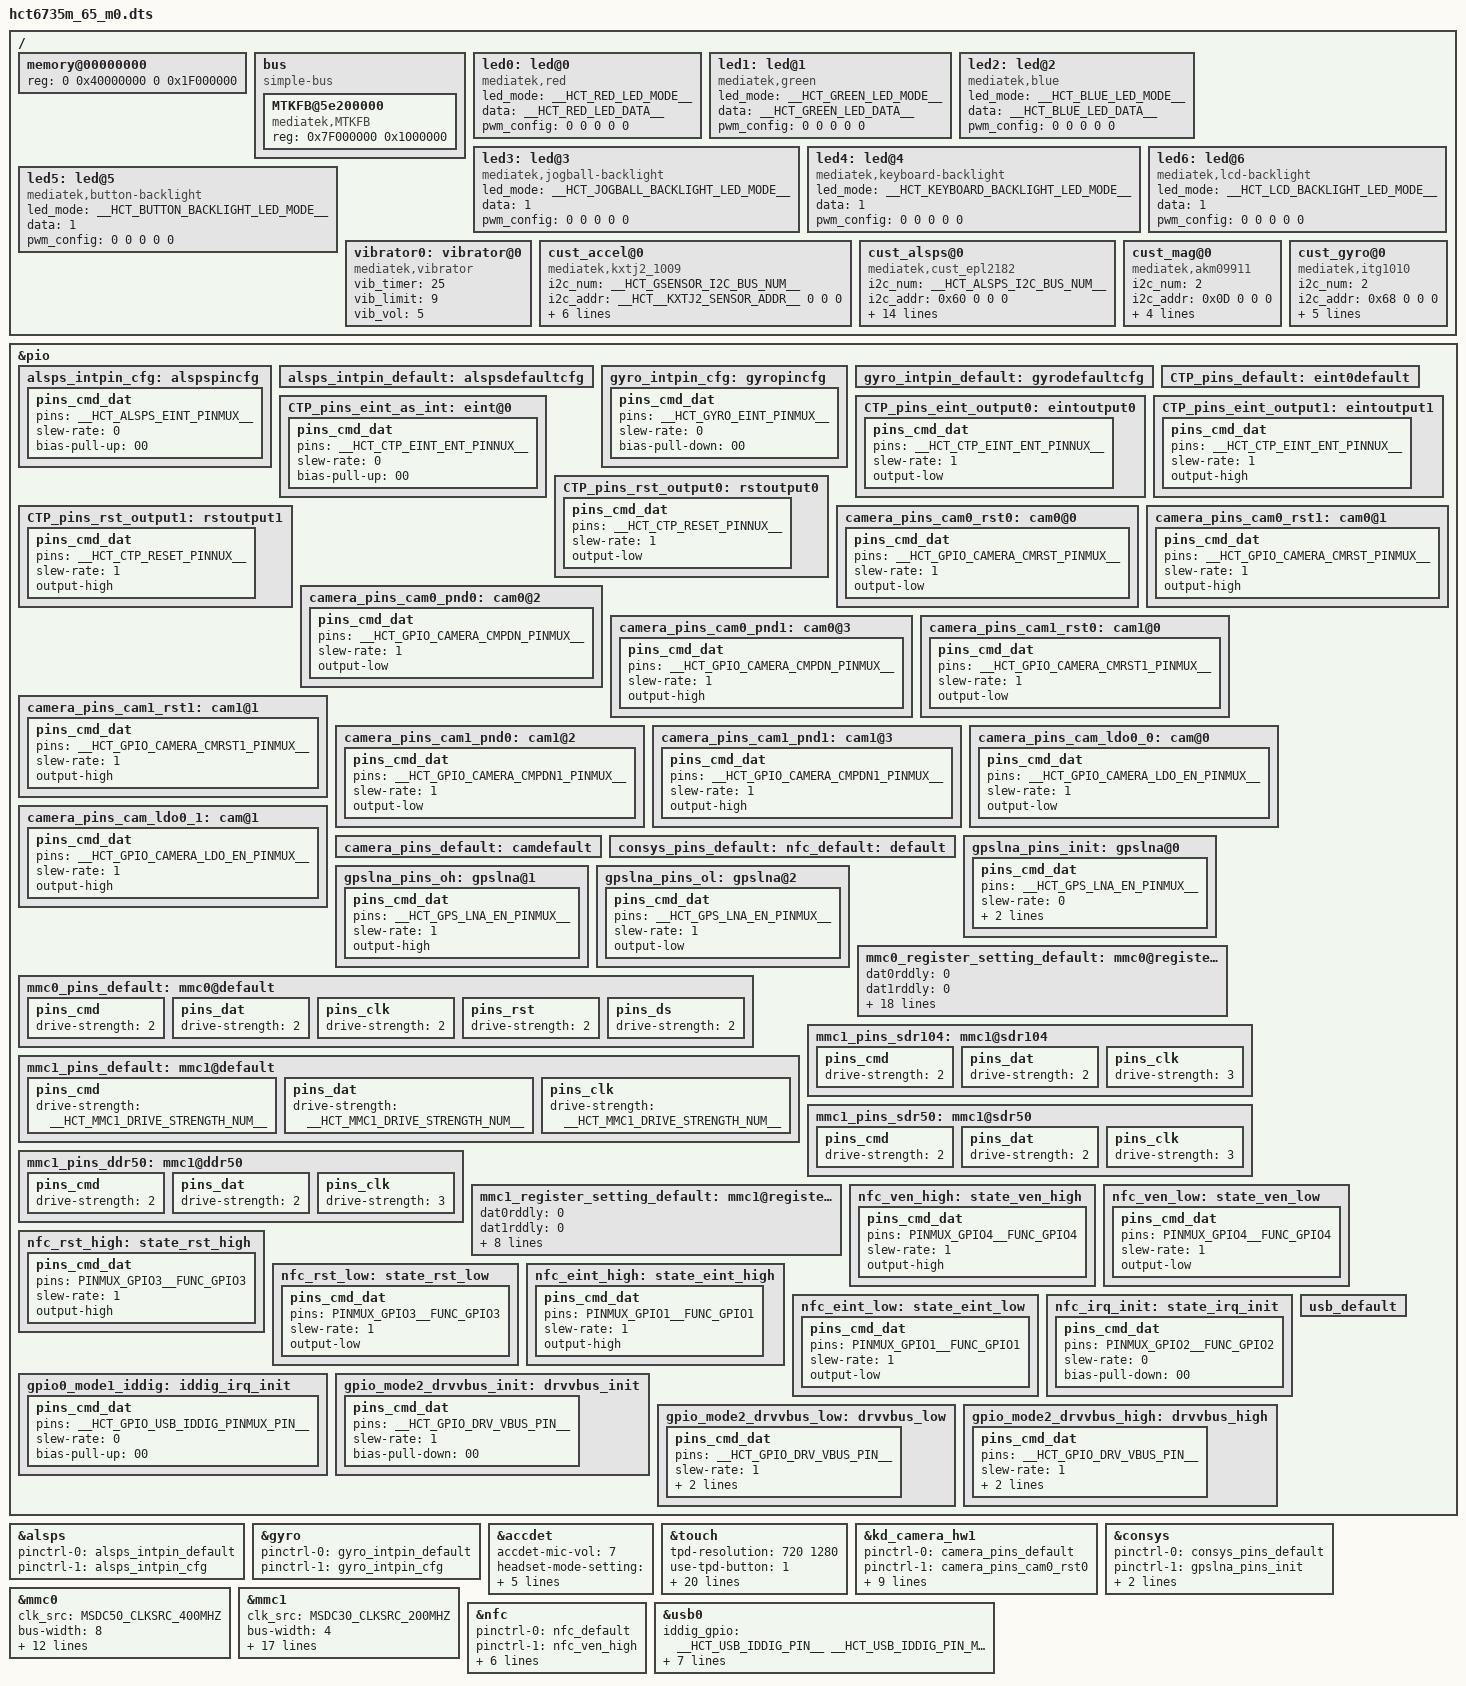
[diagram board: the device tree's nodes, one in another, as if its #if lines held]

/dts-v1/;

#include "hct_board_config.h"
#include "mt6735m.dtsi"
#include "hct_board_dts_config.h"

/ {
memory@00000000 {
		device_type = "memory";
		reg = <0 0x40000000 0 0x1F000000>;
	};

	bus {
		compatible = "simple-bus";
		#address-cells = <1>;
		#size-cells = <1>;
		ranges = <0 0 0 0xffffffff>;

		MTKFB@5e200000 {
			compatible = "mediatek,MTKFB";
			reg = <0x7F000000 0x1000000>;
		};

	};
	led0:led@0 {
		compatible = "mediatek,red";
		led_mode = <__HCT_RED_LED_MODE__>;
#if __HCT_RED_LED_MODE__ ==	__HCT_MT65XX_LED_MODE_PMIC__
		data = <__HCT_RED_LED_DATA__>;
#else
		data = <1>;
#endif
		pwm_config = <0 0 0 0 0>;
	};
	led1:led@1 {
		compatible = "mediatek,green";
		led_mode = <__HCT_GREEN_LED_MODE__>;
#if __HCT_GREEN_LED_MODE__ ==	__HCT_MT65XX_LED_MODE_PMIC__
		data = <__HCT_GREEN_LED_DATA__>;
#else
		data = <1>;
#endif
		pwm_config = <0 0 0 0 0>;
	};
	led2:led@2 {
		compatible = "mediatek,blue";
		led_mode = <__HCT_BLUE_LED_MODE__>;
#if __HCT_BLUE_LED_MODE__ ==	__HCT_MT65XX_LED_MODE_PMIC__
		data = <__HCT_BLUE_LED_DATA__>;
#else
		data = <1>;
#endif
		pwm_config = <0 0 0 0 0>;
	};
	led3:led@3 {
		compatible = "mediatek,jogball-backlight";
		led_mode = <__HCT_JOGBALL_BACKLIGHT_LED_MODE__>;
		data = <1>;
		pwm_config = <0 0 0 0 0>;
	};
	led4:led@4 {
		compatible = "mediatek,keyboard-backlight";
		led_mode = <__HCT_KEYBOARD_BACKLIGHT_LED_MODE__>;
		data = <1>;
		pwm_config = <0 0 0 0 0>;
	};
	led5:led@5 {
		compatible = "mediatek,button-backlight";
		led_mode = <__HCT_BUTTON_BACKLIGHT_LED_MODE__>;
		data = <1>;
		pwm_config = <0 0 0 0 0>;
	};
	led6:led@6 {
		compatible = "mediatek,lcd-backlight";
		led_mode = <__HCT_LCD_BACKLIGHT_LED_MODE__>;
		data = <1>;
		pwm_config = <0 0 0 0 0>;
	};
	vibrator0:vibrator@0 {
		compatible = "mediatek,vibrator";
		vib_timer = <25>;
		vib_limit = <9>;
		vib_vol= <5>;
	};
 /* sensor standardization */
		cust_accel@0 {
		compatible				= "mediatek,kxtj2_1009";
		i2c_num				        = <__HCT_GSENSOR_I2C_BUS_NUM__>;
		i2c_addr				= <__HCT__KXTJ2_SENSOR_ADDR__ 0 0 0>;
		direction				= <__HCT__KXTJ2_SENSOR_DIRECTION__>;
		power_id				= <0xffff>;
		power_vol				= <0>;
		firlen					= <0>;
		is_batch_supported			= <__HCT__KXTJ2_SENSOR_BATCH_SUPPORT__>;
		};

		cust_alsps@0 {
		compatible				= "mediatek,cust_epl2182";
		i2c_num				= <__HCT_ALSPS_I2C_BUS_NUM__>;
		i2c_addr				= <0x60 0 0 0>;
		polling_mode_ps			= <0>;
		polling_mode_als		= <1>;
		power_id				= <0xffff>;
		power_vol				= <0>;
		als_level = <0 328 861 1377 3125 7721 7767 12621 23062 28430 33274 47116 57694 57694 65535>;
		als_value = <0 133 304 502 1004 2005 3058 5005 8008 10010 12000 16000 20000 20000 20000 20000>;
		ps_threshold_high		=  <__HCT_EPL2182_PS_THRELD_HIGH__>;
		ps_threshold_low		=  <__HCT_EPL2182_PS_THRELD_LOW__>;
		is_batch_supported_ps	= <0>;
		is_batch_supported_als	= <0>;
		};

		cust_mag@0 {
		compatible				= "mediatek,akm09911";
		i2c_num					= <2>;
		i2c_addr				= <0x0D 0 0 0>;
		direction				= <1>;
		power_id				= <0xffff>;
		power_vol				= <0>;
		is_batch_supported			= <0>;
		};

		cust_gyro@0 {
		compatible				= "mediatek,itg1010";
		i2c_num					= <2>;
		i2c_addr				= <0x68 0 0 0>;
		direction				= <3>;
		power_id				= <0xffff>;
		power_vol				= <0>;
		firlen					= <0>;
		is_batch_supported			= <0>;
		};
};
/* sensor gpio standization */
&pio {
	alsps_intpin_cfg: alspspincfg {
#if __HCT_ALSPS_EINT_PINMUX__
	    pins_cmd_dat {
			pins = <__HCT_ALSPS_EINT_PINMUX__>;
			slew-rate = <0>;
			bias-pull-up = <00>;
		};
#endif
	};

	alsps_intpin_default: alspsdefaultcfg {

	};

	gyro_intpin_cfg: gyropincfg {
#if __HCT_GYRO_EINT_PINMUX__
	    pins_cmd_dat {
			pins = <__HCT_GYRO_EINT_PINMUX__>;
			slew-rate = <0>;
			bias-pull-down = <00>;
		};
#endif
	};

	gyro_intpin_default: gyrodefaultcfg {

	};
};
&alsps {
	pinctrl-names = "pin_default", "pin_cfg";
	pinctrl-0 = <&alsps_intpin_default>;
	pinctrl-1 = <&alsps_intpin_cfg>;
	status = "okay";

};

&gyro {
	pinctrl-names = "pin_default", "pin_cfg";
	pinctrl-0 = <&gyro_intpin_default>;
	pinctrl-1 = <&gyro_intpin_cfg>;
	status = "okay";

};
/* sensor end */
&accdet {
		accdet-mic-vol = <7>;
		headset-mode-setting = <0x500 0x200 1 0x1F0 0x800 0x800 0x20>;
		accdet-plugout-debounce = <20>;
		/*1:ACC mode, 2:low cost without in bias, 6:low cost with in bias*/
		accdet-mic-mode = <__HCT_ACCDET_MIC_MODE__>;
		/*0--MD_MAX--UP_MAX--DW_MAX*/
		headset-three-key-threshold = <0 80 220 500>;
		/*0--MD_MAX--VOICE_MAX--UP_MAX--DW_MAX*/
		headset-four-key-threshold = <0 58 121 192 450>;
};
&touch {
	tpd-resolution = <720 1280>;
	use-tpd-button = <1>;
	tpd-key-num = <3>;
	tpd-key-local= <139 172 158 0>;
	tpd-key-dim-local = <66 2000 100 40 300 2000 100 40 418 2000 100 40 0 0 0 0>;
	tpd-max-touch-num = <5>;
	tpd-filter-enable = <1>;
	tpd-filter-pixel-density = <93>;
	tpd-filter-custom-prameters = <0 0 0 0 0 0 0 0 0 0 0 0>;
	tpd-filter-custom-speed = <0 0 0>;
	pinctrl-names = "default", "state_eint_as_int", "state_eint_output0", "state_eint_output1",
		"state_rst_output0", "state_rst_output1","state_eint_as_int_bias_dis","aw9136_int_as_eint","aw9136_pdn_out0","aw9136_pdn_out1";
	pinctrl-0 = <&CTP_pins_default>;
	pinctrl-1 = <&CTP_pins_eint_as_int>;
	pinctrl-2 = <&CTP_pins_eint_output0>;
	pinctrl-3 = <&CTP_pins_eint_output1>;
	pinctrl-4 = <&CTP_pins_rst_output0>;
	pinctrl-5 = <&CTP_pins_rst_output1>;
	pinctrl-6 = <&ctp_pins_eint_as_int_bias_disable>;
	pinctrl-7 = <&CTP_pins_aw9136_int_as_eint>;
	pinctrl-8 = <&CTP_pins_aw9136_pdn_out0>;
	pinctrl-9 = <&CTP_pins_aw9136_pdn_out1>;
	status = "okay";
};
&pio {
	CTP_pins_default: eint0default {
	};
	CTP_pins_eint_as_int: eint@0 {
		pins_cmd_dat {
			pins = <__HCT_CTP_EINT_ENT_PINNUX__>;
			slew-rate = <0>;
			bias-pull-up = <00>;
		};
	};
	CTP_pins_eint_output0: eintoutput0 {
		pins_cmd_dat {
			pins = <__HCT_CTP_EINT_ENT_PINNUX__>;
			slew-rate = <1>;
			output-low;
		};
	};
	CTP_pins_eint_output1: eintoutput1 {
		pins_cmd_dat {
			pins = <__HCT_CTP_EINT_ENT_PINNUX__>;
			slew-rate = <1>;
			output-high;
		};
	};
	CTP_pins_rst_output0: rstoutput0 {
		pins_cmd_dat {
			pins = <__HCT_CTP_RESET_PINNUX__>;
			slew-rate = <1>;
			output-low;
		};
	};
	CTP_pins_rst_output1: rstoutput1 {
		pins_cmd_dat {
			pins = <__HCT_CTP_RESET_PINNUX__>;
			slew-rate = <1>;
			output-high;
		};
	};
};
/* TOUCH end */
/* CAMERA GPIO standardization */
&pio {
	camera_pins_cam0_rst0: cam0@0 {
	    pins_cmd_dat {
			pins = <__HCT_GPIO_CAMERA_CMRST_PINMUX__>;/*GPIO_CAMERA_CMRST_PIN*/
			slew-rate = <1>; /*direction 0:in, 1:out*/
			output-low;/*direction out used only. output_low or high*/
		};
	};
	camera_pins_cam0_rst1: cam0@1 {
	    pins_cmd_dat {
			pins = <__HCT_GPIO_CAMERA_CMRST_PINMUX__>;/*GPIO_CAMERA_CMRST_PIN*/
			slew-rate = <1>;
			output-high;
		};
	};
	camera_pins_cam0_pnd0: cam0@2 {
	    pins_cmd_dat {
			pins = <__HCT_GPIO_CAMERA_CMPDN_PINMUX__>;/*GPIO_CAMERA_CMPDN_PIN*/
			slew-rate = <1>;
			output-low;
		};
	};
	camera_pins_cam0_pnd1: cam0@3 {
	    pins_cmd_dat {
			pins = <__HCT_GPIO_CAMERA_CMPDN_PINMUX__>;/*GPIO_CAMERA_CMPDN_PIN*/
			slew-rate = <1>;
			output-high;
		};
	};
	camera_pins_cam1_rst0: cam1@0 {
	    pins_cmd_dat {
			pins = <__HCT_GPIO_CAMERA_CMRST1_PINMUX__>;/*GPIO_CAMERA_CMRST1_PIN*/
			slew-rate = <1>; /*direction 0:in, 1:out*/
			output-low;/*direction out used only. output_low or high*/
		};
	};
	camera_pins_cam1_rst1: cam1@1 {
	    pins_cmd_dat {
			pins = <__HCT_GPIO_CAMERA_CMRST1_PINMUX__>;/*GPIO_CAMERA_CMRST1_PIN*/
			slew-rate = <1>;
			output-high;
		};
	};
	camera_pins_cam1_pnd0: cam1@2 {
	    pins_cmd_dat {
			pins = <__HCT_GPIO_CAMERA_CMPDN1_PINMUX__>;/*GPIO_CAMERA_CMPDN1_PIN*/
			slew-rate = <1>;
			output-low;
		};
	};
	camera_pins_cam1_pnd1: cam1@3 {
	    pins_cmd_dat {
			pins = <__HCT_GPIO_CAMERA_CMPDN1_PINMUX__>;/*GPIO_CAMERA_CMPDN1_PIN*/
			slew-rate = <1>;
			output-high;
		};
	};
	camera_pins_cam_ldo0_0: cam@0 {
#if __HCT_GPIO_CAMERA_LDO_EN_PINMUX__
	    pins_cmd_dat {
			pins = <__HCT_GPIO_CAMERA_LDO_EN_PINMUX__>;/*GPIO_SPI_MOSI_PIN*/
			slew-rate = <1>;
			output-low;
		};
#endif
	};
	camera_pins_cam_ldo0_1: cam@1 {
#if __HCT_GPIO_CAMERA_LDO_EN_PINMUX__
		pins_cmd_dat {
			pins = <__HCT_GPIO_CAMERA_LDO_EN_PINMUX__>;/*GPIO_SPI_MOSI_PIN*/
			slew-rate = <1>;
			output-high;
		};
#endif
	};
	camera_pins_default: camdefault {
	};

};

&kd_camera_hw1 {
	pinctrl-names = "default", "cam0_rst0", "cam0_rst1", "cam0_pnd0", "cam0_pnd1",
			"cam1_rst0", "cam1_rst1", "cam1_pnd0", "cam1_pnd1","cam_ldo0_0", "cam_ldo0_1";
	pinctrl-0 = <&camera_pins_default>;
	pinctrl-1 = <&camera_pins_cam0_rst0>;
	pinctrl-2 = <&camera_pins_cam0_rst1>;
	pinctrl-3 = <&camera_pins_cam0_pnd0>;
	pinctrl-4 = <&camera_pins_cam0_pnd1>;
	pinctrl-5 = <&camera_pins_cam1_rst0>;
	pinctrl-6 = <&camera_pins_cam1_rst1>;
	pinctrl-7 = <&camera_pins_cam1_pnd0>;
	pinctrl-8 = <&camera_pins_cam1_pnd1>;
	pinctrl-9 = <&camera_pins_cam_ldo0_0>;
	pinctrl-10 = <&camera_pins_cam_ldo0_1>;
	status = "okay";

};
/* CAMERA GPIO end */

/* CONSYS GPIO standardization */
&pio {
	consys_pins_default: default {

	};

	gpslna_pins_init: gpslna@0 {
#if __HCT_GPS_LNA_EN_PINMUX__
	    pins_cmd_dat {
			pins = <__HCT_GPS_LNA_EN_PINMUX__>;
			slew-rate = <0>;
			bias-disable;
			output-low;

		};
#endif
	};

	gpslna_pins_oh: gpslna@1 {
#if __HCT_GPS_LNA_EN_PINMUX__
	    pins_cmd_dat {
			pins = <__HCT_GPS_LNA_EN_PINMUX__>;
			slew-rate = <1>;
			output-high;
		};
#endif
	};

	gpslna_pins_ol: gpslna@2 {
#if __HCT_GPS_LNA_EN_PINMUX__
	    pins_cmd_dat {
			pins = <__HCT_GPS_LNA_EN_PINMUX__>;
			slew-rate = <1>;
			output-low;
		};
#endif
	};

};

&consys {
	pinctrl-names = "default", "gps_lna_state_init", "gps_lna_state_oh", "gps_lna_state_ol";
	pinctrl-0 = <&consys_pins_default>;
	pinctrl-1 = <&gpslna_pins_init>;
	pinctrl-2 = <&gpslna_pins_oh>;
	pinctrl-3 = <&gpslna_pins_ol>;
	status = "okay";

};
/* CONSYS end */

/* mmc start */
&mmc0 {
		clk_src = /bits/ 8 <MSDC50_CLKSRC_400MHZ>;
		bus-width = <8>;
		max-frequency = <200000000>;
		cap-mmc-highspeed;
		msdc-sys-suspend;
		mmc-ddr-1_8v;
		mmc-hs200-1_8v;
		mmc-hs400-1_8v;
		non-removable;
		pinctl = <&mmc0_pins_default>;
		register_setting = <&mmc0_register_setting_default>;
		host_function = /bits/ 8 <MSDC_EMMC>;
		bootable;
		status = "okay";
};

&mmc1 {
		clk_src = /bits/ 8 <MSDC30_CLKSRC_200MHZ>;
		bus-width = <4>;
		max-frequency = <200000000>;
		msdc-sys-suspend;
		cap-sd-highspeed;
		sd-uhs-sdr12;
		sd-uhs-sdr25;
		sd-uhs-sdr50;
		sd-uhs-sdr104;
		sd-uhs-ddr50;
		pinctl = <&mmc1_pins_default>;
		pinctl_sdr104 = <&mmc1_pins_sdr104>;
		pinctl_sdr50 = <&mmc1_pins_sdr50>;
		pinctl_ddr50 = <&mmc1_pins_ddr50>;
		register_setting = <&mmc1_register_setting_default>;
		host_function = /bits/ 8 <MSDC_SD>;
		cd_level = /bits/ 8 <MSDC_CD_LOW>;
#if __HCT_SD_CARD_HOTPLUG_SUPPORT__
		cd-gpios = <&pio __HCT_MSDC_CD_GPIO_PIN_NUM__ 0>;
#else
		non-removable;
#endif
		status = "okay";
};

&pio {
	mmc0_pins_default: mmc0@default {
			pins_cmd {
				drive-strength = /bits/ 8 <2>;
			};
			pins_dat {
				drive-strength = /bits/ 8 <2>;
			};
			pins_clk {
				drive-strength = /bits/ 8 <2>;
			};
			pins_rst {
				drive-strength = /bits/ 8 <2>;
			};
			pins_ds {
				drive-strength = /bits/ 8 <2>;
			};
	};

	mmc0_register_setting_default: mmc0@register_default {
		dat0rddly      = /bits/ 8 <0>;
		dat1rddly      = /bits/ 8 <0>;
		dat2rddly      = /bits/ 8 <0>;
		dat3rddly      = /bits/ 8 <0>;
		dat4rddly      = /bits/ 8 <0>;
		dat5rddly      = /bits/ 8 <0>;
		dat6rddly      = /bits/ 8 <0>;
		dat7rddly      = /bits/ 8 <0>;
		datwrddly      = /bits/ 8 <0>;
		cmdrrddly      = /bits/ 8 <0>;
		cmdrddly       = /bits/ 8 <0>;
		cmd_edge = /bits/ 8 <MSDC_SMPL_FALLING>;
		rdata_edge = /bits/ 8 <MSDC_SMPL_FALLING>;
		wdata_edge = /bits/ 8 <MSDC_SMPL_FALLING>;

		ett-hs200-cells = <12>;
		ett-hs200-default = <OFFSET_MSDC_PATCH_BIT0	MSDC_PB0_INT_DAT_LATCH_CK_SEL 0x0
			OFFSET_MSDC_PATCH_BIT0	MSDC_PB0_CKGEN_MSDC_DLY_SEL   0x0
			OFFSET_MSDC_PATCH_BIT1	MSDC_PB1_CMD_RSP_TA_CNTR      0x1
			OFFSET_MSDC_IOCON		MSDC_IOCON_RSPL               0x1
			OFFSET_MSDC_PAD_TUNE0	MSDC_PAD_TUNE0_CMDRDLY        0x0
			OFFSET_MSDC_PAD_TUNE0	MSDC_PAD_TUNE0_CMDRRDLY       0x6
			OFFSET_MSDC_PATCH_BIT1		MSDC_PB1_WRDAT_CRCS_TA_CNTR   0x1
			OFFSET_MSDC_PAD_TUNE0	MSDC_PAD_TUNE0_DATWRDLY       0xf
			OFFSET_MSDC_IOCON			MSDC_IOCON_W_D0SPL            0x1
			OFFSET_MSDC_DAT_RDDLY0		MSDC_DAT_RDDLY0_D0            0x5
			OFFSET_MSDC_PAD_TUNE0	MSDC_PAD_TUNE0_DATRRDLY       0x12
			OFFSET_MSDC_IOCON		MSDC_IOCON_R_D_SMPL           0x0>;

		ett-hs400-cells = <8>;
		ett-hs400-default = <OFFSET_MSDC_PATCH_BIT0	MSDC_PB0_INT_DAT_LATCH_CK_SEL	0x0
			OFFSET_MSDC_PATCH_BIT0		MSDC_PB0_CKGEN_MSDC_DLY_SEL		0x0
			OFFSET_EMMC50_PAD_DS_TUNE	MSDC_EMMC50_PAD_DS_TUNE_DLY1	0x7
			OFFSET_EMMC50_PAD_DS_TUNE	MSDC_EMMC50_PAD_DS_TUNE_DLY3	0x12
			OFFSET_MSDC_PATCH_BIT1			MSDC_PB1_CMD_RSP_TA_CNTR	0x1
			OFFSET_MSDC_IOCON		MSDC_IOCON_RSPL				0x1
			OFFSET_MSDC_PAD_TUNE0			MSDC_PAD_TUNE0_CMDRDLY		0x0
			OFFSET_MSDC_PAD_TUNE0		MSDC_PAD_TUNE0_CMDRRDLY		0xb>;
	};

	mmc1_pins_default: mmc1@default {
#if defined(__HCT_MMC1_DRIVE_STRENGTH_NUM__)
			pins_cmd {
				drive-strength = /bits/ 8 <__HCT_MMC1_DRIVE_STRENGTH_NUM__>;
			};
			pins_dat {
				drive-strength = /bits/ 8 <__HCT_MMC1_DRIVE_STRENGTH_NUM__>;
			};
			pins_clk {
				drive-strength = /bits/ 8 <__HCT_MMC1_DRIVE_STRENGTH_NUM__>;
			};
#else
			pins_cmd {
				drive-strength = /bits/ 8 <3>;
			};
			pins_dat {
				drive-strength = /bits/ 8 <3>;
			};
			pins_clk {
				drive-strength = /bits/ 8 <3>;
			};
#endif
	};

	mmc1_pins_sdr104: mmc1@sdr104 {
			pins_cmd {
				drive-strength = /bits/ 8 <2>;
			};
			pins_dat {
				drive-strength = /bits/ 8 <2>;
			};
			pins_clk {
				drive-strength = /bits/ 8 <3>;
			};
	};

	mmc1_pins_sdr50: mmc1@sdr50 {
			pins_cmd {
				drive-strength = /bits/ 8 <2>;
			};
			pins_dat {
				drive-strength = /bits/ 8 <2>;
			};
			pins_clk {
				drive-strength = /bits/ 8 <3>;
			};
	};

	mmc1_pins_ddr50: mmc1@ddr50 {
			pins_cmd {
				drive-strength = /bits/ 8 <2>;
			};
			pins_dat {
				drive-strength = /bits/ 8 <2>;
			};
			pins_clk {
				drive-strength = /bits/ 8 <3>;
			};
	};

	mmc1_register_setting_default: mmc1@register_default {
				dat0rddly      = /bits/ 8 <0>;
				dat1rddly      = /bits/ 8 <0>;
				dat2rddly      = /bits/ 8 <0>;
				dat3rddly      = /bits/ 8 <0>;
				datwrddly      = /bits/ 8 <0>;
				cmdrrddly      = /bits/ 8 <0>;
				cmdrddly       = /bits/ 8 <0>;
				cmd_edge = /bits/ 8 <MSDC_SMPL_FALLING>;
				rdata_edge = /bits/ 8 <MSDC_SMPL_FALLING>;
				wdata_edge = /bits/ 8 <MSDC_SMPL_FALLING>;
	};
};
/* mmc end */

/* NFC GPIO standardization */
&pio {
	nfc_default: default {

	};

	nfc_ven_high: state_ven_high {
		pins_cmd_dat {
			pins = <PINMUX_GPIO4__FUNC_GPIO4>;
			slew-rate = <1>;
			output-high;
		};
	};

	nfc_ven_low: state_ven_low {
		pins_cmd_dat {
			pins = <PINMUX_GPIO4__FUNC_GPIO4>;
			slew-rate = <1>;
			output-low;
		};
	};

	nfc_rst_high: state_rst_high {
		pins_cmd_dat {
			pins = <PINMUX_GPIO3__FUNC_GPIO3>;
			slew-rate = <1>;
			output-high;
		};
	};

	nfc_rst_low: state_rst_low {
		pins_cmd_dat {
			pins = <PINMUX_GPIO3__FUNC_GPIO3>;
			slew-rate = <1>;
			output-low;
		};
	};

	nfc_eint_high: state_eint_high {
		pins_cmd_dat {
			pins = <PINMUX_GPIO1__FUNC_GPIO1>;
			slew-rate = <1>;
			output-high;
		};
	};

	nfc_eint_low: state_eint_low {
		pins_cmd_dat {
			pins = <PINMUX_GPIO1__FUNC_GPIO1>;
			slew-rate = <1>;
			output-low;
		};
	};

	nfc_irq_init: state_irq_init {
		pins_cmd_dat {
			pins = <PINMUX_GPIO2__FUNC_GPIO2>;
			slew-rate = <0>;
			bias-pull-down = <00>;
		};
	};
};

&nfc {
	pinctrl-names = "default", "ven_high", "ven_low", "rst_high", "rst_low", "eint_high", "eint_low", "irq_init";
	pinctrl-0 = <&nfc_default>;
	pinctrl-1 = <&nfc_ven_high>;
	pinctrl-2 = <&nfc_ven_low>;
	pinctrl-3 = <&nfc_rst_high>;
	pinctrl-4 = <&nfc_rst_low>;
	pinctrl-5 = <&nfc_eint_high>;
	pinctrl-6 = <&nfc_eint_low>;
	pinctrl-7 = <&nfc_irq_init>;
	status = "okay";
};
/* NFC end */

/* USB GPIO Kernal Standardization start */
#if __HCT_USB_MTK_OTG_SUPPORT__
&pio {
	usb_default: usb_default {
	};

	gpio0_mode1_iddig: iddig_irq_init {
		pins_cmd_dat {
#if __HCT_GPIO_USB_IDDIG_PINMUX_PIN__
			pins = <__HCT_GPIO_USB_IDDIG_PINMUX_PIN__>;
#else
			pins = <PINMUX_GPIO0__FUNC_IDDIG>;
#endif
			slew-rate = <0>;
			bias-pull-up = <00>;
		};
	};

	gpio_mode2_drvvbus_init: drvvbus_init {
		pins_cmd_dat {
			pins = <__HCT_GPIO_DRV_VBUS_PIN__>;
			slew-rate = <1>;
			bias-pull-down = <00>;
		};
	};

	gpio_mode2_drvvbus_low: drvvbus_low {
		pins_cmd_dat {
			pins = <__HCT_GPIO_DRV_VBUS_PIN__>;
			slew-rate = <1>;
			output-low;
			bias-pull-down = <00>;
		};
	};

	gpio_mode2_drvvbus_high: drvvbus_high {
		pins_cmd_dat {
			pins = <__HCT_GPIO_DRV_VBUS_PIN__>;
			slew-rate = <1>;
			output-high;
			bias-pull-down = <00>;
		};
	};
};

&usb0 {
	iddig_gpio = <__HCT_USB_IDDIG_PIN__ __HCT_USB_IDDIG_PIN_MODE__>;
	drvvbus_gpio = <__HCT_USB_VBUS_EN_PIN__ __HCT_USB_VBUS_EN_PIN_MODE__>;
	pinctrl-names = "usb_default", "iddig_irq_init", "drvvbus_init", "drvvbus_low", "drvvbus_high";
	pinctrl-0 = <&usb_default>;
	pinctrl-1 = <&gpio0_mode1_iddig>;
	pinctrl-2 = <&gpio_mode2_drvvbus_init>;
	pinctrl-3 = <&gpio_mode2_drvvbus_low>;
	pinctrl-4 = <&gpio_mode2_drvvbus_high>;
	status = "okay";
};
#endif

/* USB GPIO Kernal Standardization end */


#include "hct_board.dts"
